# PIC18LF8720 register map
Vendor: Microchip
Registers are 8-bit, read-write, no defined reset value unless marked. A register's access mark holds for its fields unless they carry their own. Addresses are absolute, and some are shared; only a register's first bit layout is shown; [hi:lo] are bit positions.

## CONFIG — Configuration words, addresses in ProgramSpace
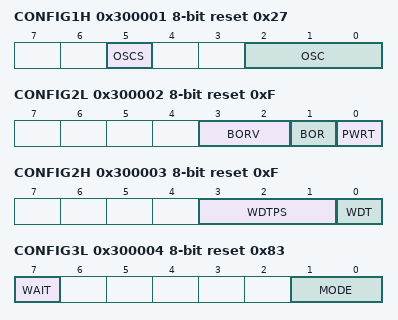
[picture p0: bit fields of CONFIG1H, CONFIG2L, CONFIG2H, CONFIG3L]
0x300001 CONFIG1H reset 0x27
  [5] OSCS — Oscillator System Clock Switch Enable bit
    1=OFF (Oscillator system clock switch option is disabled (main oscillator is source)); 0=ON (Timer1 Oscillator system clock switch option is enabled (oscillator switching is enabled))
  [2:0] OSC — Oscillator Selection bits
    7=RCIO (RC oscillator w/ OSC2 configured as RA6); 6=HSPLL (HS oscillator with PLL enabled; clock frequency = (4 x FOSC)); 5=ECIO (EC oscillator w/ OSC2 configured as RA6); 4=EC (EC oscillator w/ OSC2 configured as divide-by-4 clock output); 3=RC (RC oscillator w/ OSC2 configured as divide-by-4 clock output); 2=HS (HS oscillator); 1=XT (XT oscillator); 0=LP (LP oscillator)
0x300002 CONFIG2L reset 0xF
  [3:2] BORV — Brown-out Reset Voltage bits
    3=VBOR set to 2.5V; 2=VBOR set to 2.7V; 1=VBOR set to 4.2V; 0=VBOR set to 4.5V
  [1] BOR — Brown-out Reset Enable bit
    1=ON (Brown-out Reset enabled); 0=OFF (Brown-out Reset disabled)
  [0] PWRT — Power-up Timer Enable bit
    1=OFF (PWRT disabled); 0=ON (PWRT enabled)
0x300003 CONFIG2H reset 0xF
  [3:1] WDTPS — Watchdog Timer Postscale Select bits
    7=1:128; 6=1:64; 5=1:32; 4=1:16; 3=1:8; 2=1:4; 1=1:2; 0=1:1
  [0] WDT — Watchdog Timer Enable bit
    1=ON (WDT enabled); 0=OFF (WDT disabled (control is placed on the SWDTEN bit))
0x300004 CONFIG3L reset 0x83
  [7] WAIT — External Bus Data Wait Enable bit
    1=OFF (Wait selections unavailable for table reads and table writes); 0=ON (Wait selections for table reads and table writes are determined by the WAIT1:WAIT0 bits (MEMCOM<5:4>))
  [1:0] MODE — Processor Mode Select bits
    3=MC (Microcontroller mode); 2=MP (Microprocessor mode); 1=MPB (Microprocessor with Boot Block mode); 0=EM (Extended Microcontroller mode)
0x300005 CONFIG3H reset 0x3
  [0] CCP2MUX — CCP2 Mux bit
    1=ON (CCP2 input/output is multiplexed with RC1); 0=OFF (CCP2 is multiplexed with RB3 in Extended Microcontroller, Microprocessor or Microprocessor with Boot Block mode. Or with RE7 in Microcontroller mode.)
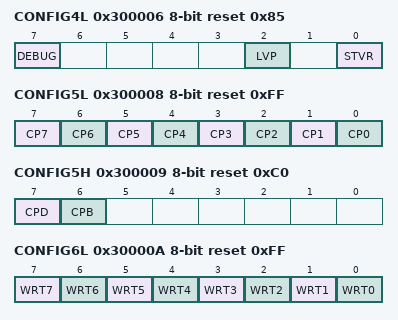
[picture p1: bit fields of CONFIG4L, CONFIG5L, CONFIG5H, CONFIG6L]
0x300006 CONFIG4L reset 0x85
  [7] DEBUG — Background Debugger Enable bit
    1=OFF (Background debugger disabled. RB6 and RB7 configured as general purpose I/O pins.); 0=ON (Background debugger enabled. RB6 and RB7 are dedicated to In-Circuit Debug.)
  [2] LVP — Low-Voltage ICSP Enable bit
    1=ON (Low-voltage ICSP enabled); 0=OFF (Low-voltage ICSP disabled)
  [0] STVR — Stack Full/Underflow Reset Enable bit
    1=ON (Stack full/underflow will cause Reset); 0=OFF (Stack full/underflow will not cause Reset)
0x300008 CONFIG5L reset 0xFF
  [7] CP7 — Code Protection bit
    1=OFF (Block 7 (01C000-01FFFFh) not code-protected); 0=ON (Block 7 (01C000-01FFFFh) code-protected)
  [6] CP6 — Code Protection bit
    1=OFF (Block 6 (018000-01BFFFh) not code-protected); 0=ON (Block 6 (018000-01BFFFh) code-protected)
  [5] CP5 — Code Protection bit
    1=OFF (Block 5 (014000-017FFFh) not code-protected); 0=ON (Block 5 (014000-017FFFh) code-protected)
  [4] CP4 — Code Protection bit
    1=OFF (Block 4 (010000-013FFFh) not code-protected); 0=ON (Block 4 (010000-013FFFh) code-protected)
  [3] CP3 — Code Protection bit
    1=OFF (Block 3 (00C000-00FFFFh) not code-protected); 0=ON (Block 3 (00C000-00FFFFh) code-protected)
  [2] CP2 — Code Protection bit
    1=OFF (Block 2 (008000-00BFFFh) not code-protected); 0=ON (Block 2 (008000-00BFFFh) code-protected)
  [1] CP1 — Code Protection bit
    1=OFF (Block 1 (004000-007FFFh) not code-protected); 0=ON (Block 1 (004000-007FFFh) code-protected)
  [0] CP0 — Code Protection bit
    1=OFF (Block 0 (000200-003FFFh) not code-protected); 0=ON (Block 0 (000200-003FFFh) code-protected)
0x300009 CONFIG5H reset 0xC0
  [7] CPD — Data EEPROM Code Protection bit
    1=OFF (Data EEPROM not code-protected); 0=ON (Data EEPROM code-protected)
  [6] CPB — Boot Block Code Protection bit
    1=OFF (Boot Block (000000-0001FFh) not code-protected); 0=ON (Boot Block (000000-0001FFh) code-protected)
0x30000A CONFIG6L reset 0xFF
  [7] WRT7 — Write Protection bit
    1=OFF (Block 7 (01C000-01FFFFh) not write-protected); 0=ON (Block 7 (01C000-01FFFFh) write-protected)
  [6] WRT6 — Write Protection bit
    1=OFF (Block 6 (018000-01BFFFh) not write-protected); 0=ON (Block 6 (018000-01BFFFh) write-protected)
  [5] WRT5 — Write Protection bit
    1=OFF (Block 5 (014000-017FFFh) not write-protected); 0=ON (Block 5 (014000-017FFFh) write-protected)
  [4] WRT4 — Write Protection bit
    1=OFF (Block 4 (010000-013FFFh) not write-protected); 0=ON (Block 4 (010000-013FFFh) write-protected)
  [3] WRT3 — Write Protection bit
    1=OFF (Block 3 (00C000-00FFFFh) not write-protected); 0=ON (Block 3 (00C000-00FFFFh) write-protected)
  [2] WRT2 — Write Protection bit
    1=OFF (Block 2 (008000-00BFFFh) not write-protected); 0=ON (Block 2 (008000-00BFFFh) write-protected)
  [1] WRT1 — Write Protection bit
    1=OFF (Block 1 (004000-007FFFh) not write-protected); 0=ON (Block 1 (004000-007FFFh) write-protected)
  [0] WRT0 — Write Protection bit
    1=OFF (Block 0 (000200-003FFFh) not write-protected); 0=ON (Block 0 (000200-003FFFh) write-protected)
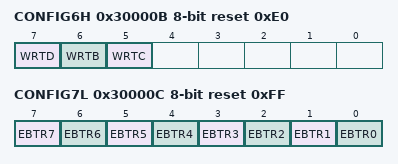
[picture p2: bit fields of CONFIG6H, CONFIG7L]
0x30000B CONFIG6H reset 0xE0
  [7] WRTD — Data EEPROM Write Protection bit
    1=OFF (Data EEPROM not write-protected); 0=ON (Data EEPROM write-protected)
  [6] WRTB — Boot Block Write Protection bit
    1=OFF (Boot Block (000000-0001FFh) not write-protected); 0=ON (Boot Block (000000-0001FFh) write-protected)
  [5] WRTC — Configuration Register Write Protection bit
    1=OFF (Configuration registers (300000-3000FFh) not write-protected); 0=ON (Configuration registers (300000-3000FFh) write-protected)
0x30000C CONFIG7L reset 0xFF
  [7] EBTR7 — Table Read Protection bit
    1=OFF (Block 7 (01C000-01FFFFh) not protected from table reads executed in other blocks); 0=ON (Block 7 (01C000-01FFFFh) protected from table reads executed in other blocks)
  [6] EBTR6 — Table Read Protection bit
    1=OFF (Block 6 (018000-01BFFFh) not protected from table reads executed in other blocks); 0=ON (Block 6 (018000-01BFFFh) protected from table reads executed in other blocks)
  [5] EBTR5 — Table Read Protection bit
    1=OFF (Block 5 (014000-017FFFh) not protected from table reads executed in other blocks); 0=ON (Block 5 (014000-017FFFh) protected from table reads executed in other blocks)
  [4] EBTR4 — Table Read Protection bit
    1=OFF (Block 4 (010000-013FFFh) not protected from table reads executed in other blocks); 0=ON (Block 4 (010000-013FFFh) protected from table reads executed in other blocks)
  [3] EBTR3 — Table Read Protection bit
    1=OFF (Block 3 (00C000-00FFFFh) not protected from table reads executed in other blocks); 0=ON (Block 3 (00C000-00FFFFh) protected from table reads executed in other blocks)
  [2] EBTR2 — Table Read Protection bit
    1=OFF (Block 2 (008000-00BFFFh) not protected from table reads executed in other blocks); 0=ON (Block 2 (008000-00BFFFh) protected from table reads executed in other blocks)
  [1] EBTR1 — Table Read Protection bit
    1=OFF (Block 1 (004000-007FFFh) not protected from table reads executed in other blocks); 0=ON (Block 1 (004000-007FFFh) protected from table reads executed in other blocks)
  [0] EBTR0 — Table Read Protection bit
    1=OFF (Block 0 (000200-003FFFh) not protected from table reads executed in other blocks); 0=ON (Block 0 (000200-003FFFh) protected from table reads executed in other blocks)
0x30000D CONFIG7H reset 0x40
  [6] EBTRB — Boot Block Table Read Protection bit
    1=OFF (Boot Block (000000-0001FFh) not protected from table reads executed in other blocks); 0=ON (Boot Block (000000-0001FFh) protected from table reads executed in other blocks)
